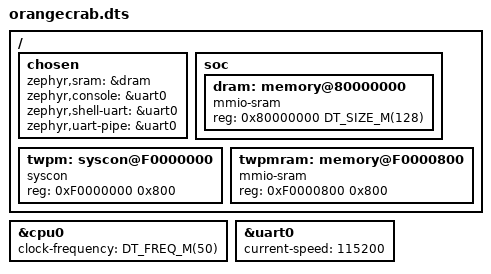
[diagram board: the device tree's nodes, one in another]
/dts-v1/;

#include <neorv32.dtsi>
#include <freq.h>
#include <mem.h>

/ {
	chosen {
		zephyr,sram = &dram;
		zephyr,console = &uart0;
		zephyr,shell-uart = &uart0;
		zephyr,uart-pipe = &uart0;
	};

	soc {
		dram: memory@80000000 {
			compatible = "mmio-sram";
			reg = <0x80000000 DT_SIZE_M(128)>;
		};
	};

	twpm: syscon@F0000000 {
		compatible = "syscon";
		status = "okay";
		reg = <0xF0000000 0x800>;
	};

	twpmram: memory@F0000800 {
		compatible = "mmio-sram";
		reg = < 0xF0000800 0x800 >;
	};
};

&cpu0 {
	clock-frequency = <DT_FREQ_M(50)>;
};

&uart0 {
	current-speed = <115200>;
	status = "okay";
};
